VERSION ""

NS_ :

BS_:

BU_: BMC CMC_01 CMC_02 CMC_03 CMC_04 CMC_05 CMC_06 CMC_07 CMC_08
VAL_TABLE_ J1939_8bit 255 "Not available" 254 "Error" ;

BO_ 186 BMC_Request_voltages: 8 BMC
 SG_ BMC_Magic_content : 0|64@1+ (1,0) [4.97229944405885E+018|4.97229944405885E+018] "Unknown"  CMC_01,CMC_02,CMC_03,CMC_04,CMC_05,CMC_06,CMC_07,CMC_08

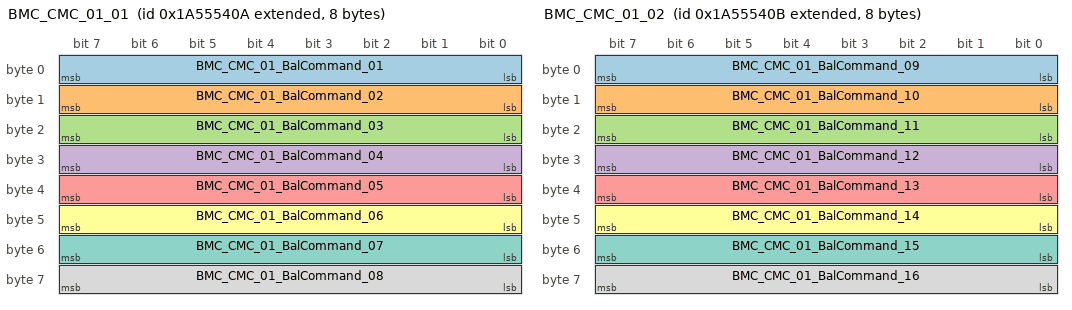
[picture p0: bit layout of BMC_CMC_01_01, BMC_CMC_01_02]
BO_ 2589283338 BMC_CMC_01_01: 8 BMC
 SG_ BMC_CMC_01_BalCommand_01 : 0|8@1+ (2,0) [0|506] "Minute"  CMC_01
 SG_ BMC_CMC_01_BalCommand_02 : 8|8@1+ (2,0) [0|506] "Minute"  CMC_01
 SG_ BMC_CMC_01_BalCommand_03 : 16|8@1+ (2,0) [0|506] "Minute"  CMC_01
 SG_ BMC_CMC_01_BalCommand_04 : 24|8@1+ (2,0) [0|506] "Minute"  CMC_01
 SG_ BMC_CMC_01_BalCommand_05 : 32|8@1+ (2,0) [0|506] "Minute"  CMC_01
 SG_ BMC_CMC_01_BalCommand_06 : 40|8@1+ (2,0) [0|506] "Minute"  CMC_01
 SG_ BMC_CMC_01_BalCommand_07 : 48|8@1+ (2,0) [0|506] "Minute"  CMC_01
 SG_ BMC_CMC_01_BalCommand_08 : 56|8@1+ (2,0) [0|506] "Minute"  CMC_01

BO_ 2589283339 BMC_CMC_01_02: 8 BMC
 SG_ BMC_CMC_01_BalCommand_09 : 0|8@1+ (2,0) [0|506] "Minute"  CMC_01
 SG_ BMC_CMC_01_BalCommand_10 : 8|8@1+ (2,0) [0|506] "Minute"  CMC_01
 SG_ BMC_CMC_01_BalCommand_11 : 16|8@1+ (2,0) [0|506] "Minute"  CMC_01
 SG_ BMC_CMC_01_BalCommand_12 : 24|8@1+ (2,0) [0|506] "Minute"  CMC_01
 SG_ BMC_CMC_01_BalCommand_13 : 32|8@1+ (2,0) [0|506] "Minute" Vector__XXX
 SG_ BMC_CMC_01_BalCommand_14 : 40|8@1+ (2,0) [0|506] "Minute" Vector__XXX
 SG_ BMC_CMC_01_BalCommand_15 : 48|8@1+ (2,0) [0|506] "Minute" Vector__XXX
 SG_ BMC_CMC_01_BalCommand_16 : 56|8@1+ (2,0) [0|506] "Minute" Vector__XXX

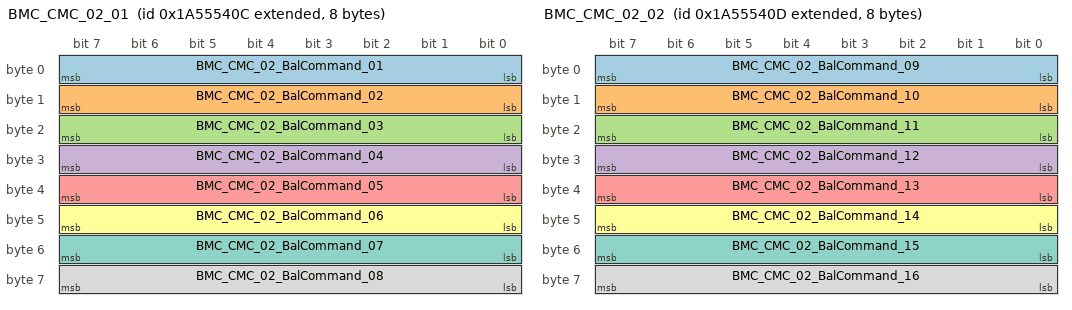
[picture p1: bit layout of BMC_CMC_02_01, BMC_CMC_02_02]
BO_ 2589283340 BMC_CMC_02_01: 8 BMC
 SG_ BMC_CMC_02_BalCommand_01 : 0|8@1+ (2,0) [0|506] "Minute"  CMC_02
 SG_ BMC_CMC_02_BalCommand_02 : 8|8@1+ (2,0) [0|506] "Minute"  CMC_02
 SG_ BMC_CMC_02_BalCommand_03 : 16|8@1+ (2,0) [0|506] "Minute"  CMC_02
 SG_ BMC_CMC_02_BalCommand_04 : 24|8@1+ (2,0) [0|506] "Minute"  CMC_02
 SG_ BMC_CMC_02_BalCommand_05 : 32|8@1+ (2,0) [0|506] "Minute"  CMC_02
 SG_ BMC_CMC_02_BalCommand_06 : 40|8@1+ (2,0) [0|506] "Minute"  CMC_02
 SG_ BMC_CMC_02_BalCommand_07 : 48|8@1+ (2,0) [0|506] "Minute"  CMC_02
 SG_ BMC_CMC_02_BalCommand_08 : 56|8@1+ (2,0) [0|506] "Minute"  CMC_02

BO_ 2589283341 BMC_CMC_02_02: 8 BMC
 SG_ BMC_CMC_02_BalCommand_09 : 0|8@1+ (2,0) [0|506] "Minute"  CMC_02
 SG_ BMC_CMC_02_BalCommand_10 : 8|8@1+ (2,0) [0|506] "Minute"  CMC_02
 SG_ BMC_CMC_02_BalCommand_11 : 16|8@1+ (2,0) [0|506] "Minute"  CMC_02
 SG_ BMC_CMC_02_BalCommand_12 : 24|8@1+ (2,0) [0|506] "Minute"  CMC_02
 SG_ BMC_CMC_02_BalCommand_13 : 32|8@1+ (2,0) [0|506] "Minute" Vector__XXX
 SG_ BMC_CMC_02_BalCommand_14 : 40|8@1+ (2,0) [0|506] "Minute" Vector__XXX
 SG_ BMC_CMC_02_BalCommand_15 : 48|8@1+ (2,0) [0|506] "Minute" Vector__XXX
 SG_ BMC_CMC_02_BalCommand_16 : 56|8@1+ (2,0) [0|506] "Minute" Vector__XXX

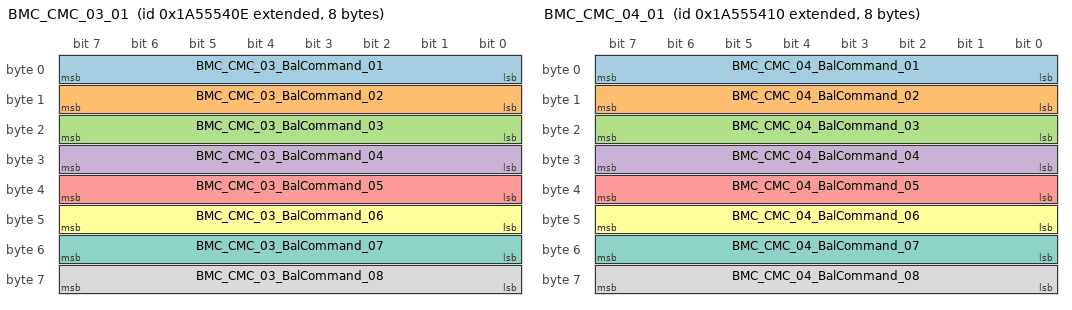
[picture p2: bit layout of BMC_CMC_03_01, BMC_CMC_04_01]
BO_ 2589283342 BMC_CMC_03_01: 8 BMC
 SG_ BMC_CMC_03_BalCommand_01 : 0|8@1+ (2,0) [0|506] "Minute"  CMC_03
 SG_ BMC_CMC_03_BalCommand_02 : 8|8@1+ (2,0) [0|506] "Minute"  CMC_03
 SG_ BMC_CMC_03_BalCommand_03 : 16|8@1+ (2,0) [0|506] "Minute"  CMC_03
 SG_ BMC_CMC_03_BalCommand_04 : 24|8@1+ (2,0) [0|506] "Minute"  CMC_03
 SG_ BMC_CMC_03_BalCommand_05 : 32|8@1+ (2,0) [0|506] "Minute"  CMC_03
 SG_ BMC_CMC_03_BalCommand_06 : 40|8@1+ (2,0) [0|506] "Minute"  CMC_03
 SG_ BMC_CMC_03_BalCommand_07 : 48|8@1+ (2,0) [0|506] "Minute"  CMC_03
 SG_ BMC_CMC_03_BalCommand_08 : 56|8@1+ (2,0) [0|506] "Minute"  CMC_03

BO_ 2589283344 BMC_CMC_04_01: 8 BMC
 SG_ BMC_CMC_04_BalCommand_01 : 0|8@1+ (2,0) [0|506] "Minute"  CMC_04
 SG_ BMC_CMC_04_BalCommand_02 : 8|8@1+ (2,0) [0|506] "Minute"  CMC_04
 SG_ BMC_CMC_04_BalCommand_03 : 16|8@1+ (2,0) [0|506] "Minute"  CMC_04
 SG_ BMC_CMC_04_BalCommand_04 : 24|8@1+ (2,0) [0|506] "Minute"  CMC_04
 SG_ BMC_CMC_04_BalCommand_05 : 32|8@1+ (2,0) [0|506] "Minute"  CMC_04
 SG_ BMC_CMC_04_BalCommand_06 : 40|8@1+ (2,0) [0|506] "Minute"  CMC_04
 SG_ BMC_CMC_04_BalCommand_07 : 48|8@1+ (2,0) [0|506] "Minute"  CMC_04
 SG_ BMC_CMC_04_BalCommand_08 : 56|8@1+ (2,0) [0|506] "Minute"  CMC_04

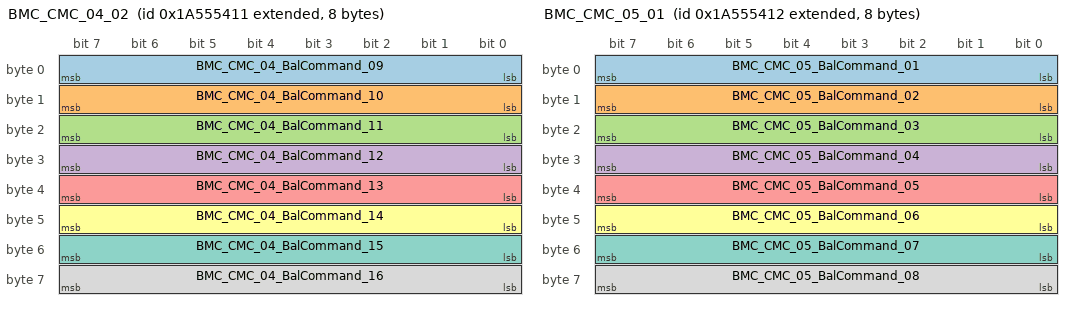
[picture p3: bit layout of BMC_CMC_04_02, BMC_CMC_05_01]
BO_ 2589283345 BMC_CMC_04_02: 8 BMC
 SG_ BMC_CMC_04_BalCommand_09 : 0|8@1+ (2,0) [0|506] "Minute"  CMC_04
 SG_ BMC_CMC_04_BalCommand_10 : 8|8@1+ (2,0) [0|506] "Minute"  CMC_04
 SG_ BMC_CMC_04_BalCommand_11 : 16|8@1+ (2,0) [0|506] "Minute" Vector__XXX
 SG_ BMC_CMC_04_BalCommand_12 : 24|8@1+ (2,0) [0|506] "Minute" Vector__XXX
 SG_ BMC_CMC_04_BalCommand_13 : 32|8@1+ (2,0) [0|506] "Minute" Vector__XXX
 SG_ BMC_CMC_04_BalCommand_14 : 40|8@1+ (2,0) [0|506] "Minute" Vector__XXX
 SG_ BMC_CMC_04_BalCommand_15 : 48|8@1+ (2,0) [0|506] "Minute" Vector__XXX
 SG_ BMC_CMC_04_BalCommand_16 : 56|8@1+ (2,0) [0|506] "Minute" Vector__XXX

BO_ 2589283346 BMC_CMC_05_01: 8 BMC
 SG_ BMC_CMC_05_BalCommand_01 : 0|8@1+ (2,0) [0|506] "Minute"  CMC_05
 SG_ BMC_CMC_05_BalCommand_02 : 8|8@1+ (2,0) [0|506] "Minute"  CMC_05
 SG_ BMC_CMC_05_BalCommand_03 : 16|8@1+ (2,0) [0|506] "Minute"  CMC_05
 SG_ BMC_CMC_05_BalCommand_04 : 24|8@1+ (2,0) [0|506] "Minute"  CMC_05
 SG_ BMC_CMC_05_BalCommand_05 : 32|8@1+ (2,0) [0|506] "Minute"  CMC_05
 SG_ BMC_CMC_05_BalCommand_06 : 40|8@1+ (2,0) [0|506] "Minute"  CMC_05
 SG_ BMC_CMC_05_BalCommand_07 : 48|8@1+ (2,0) [0|506] "Minute"  CMC_05
 SG_ BMC_CMC_05_BalCommand_08 : 56|8@1+ (2,0) [0|506] "Minute"  CMC_05

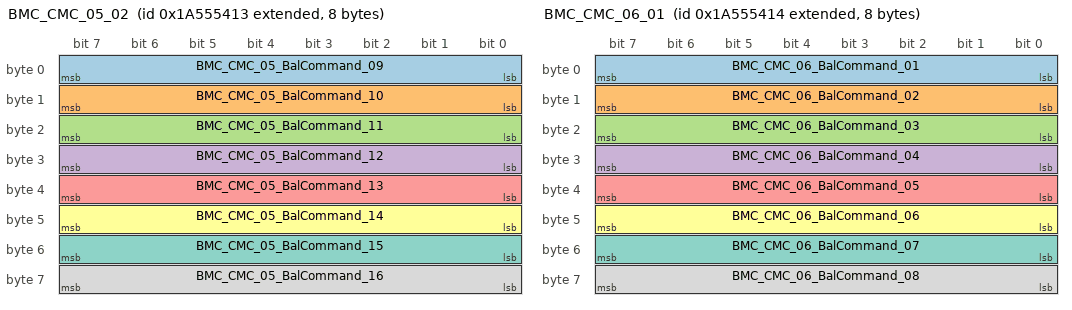
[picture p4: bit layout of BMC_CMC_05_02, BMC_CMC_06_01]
BO_ 2589283347 BMC_CMC_05_02: 8 BMC
 SG_ BMC_CMC_05_BalCommand_09 : 0|8@1+ (2,0) [0|506] "Minute"  CMC_05
 SG_ BMC_CMC_05_BalCommand_10 : 8|8@1+ (2,0) [0|506] "Minute"  CMC_05
 SG_ BMC_CMC_05_BalCommand_11 : 16|8@1+ (2,0) [0|506] "Minute"  CMC_05
 SG_ BMC_CMC_05_BalCommand_12 : 24|8@1+ (2,0) [0|506] "Minute"  CMC_05
 SG_ BMC_CMC_05_BalCommand_13 : 32|8@1+ (2,0) [0|506] "Minute" Vector__XXX
 SG_ BMC_CMC_05_BalCommand_14 : 40|8@1+ (2,0) [0|506] "Minute" Vector__XXX
 SG_ BMC_CMC_05_BalCommand_15 : 48|8@1+ (2,0) [0|506] "Minute" Vector__XXX
 SG_ BMC_CMC_05_BalCommand_16 : 56|8@1+ (2,0) [0|506] "Minute" Vector__XXX

BO_ 2589283348 BMC_CMC_06_01: 8 BMC
 SG_ BMC_CMC_06_BalCommand_01 : 0|8@1+ (2,0) [0|506] "Minute"  CMC_06
 SG_ BMC_CMC_06_BalCommand_02 : 8|8@1+ (2,0) [0|506] "Minute"  CMC_06
 SG_ BMC_CMC_06_BalCommand_03 : 16|8@1+ (2,0) [0|506] "Minute"  CMC_06
 SG_ BMC_CMC_06_BalCommand_04 : 24|8@1+ (2,0) [0|506] "Minute"  CMC_06
 SG_ BMC_CMC_06_BalCommand_05 : 32|8@1+ (2,0) [0|506] "Minute"  CMC_06
 SG_ BMC_CMC_06_BalCommand_06 : 40|8@1+ (2,0) [0|506] "Minute"  CMC_06
 SG_ BMC_CMC_06_BalCommand_07 : 48|8@1+ (2,0) [0|506] "Minute"  CMC_06
 SG_ BMC_CMC_06_BalCommand_08 : 56|8@1+ (2,0) [0|506] "Minute"  CMC_06

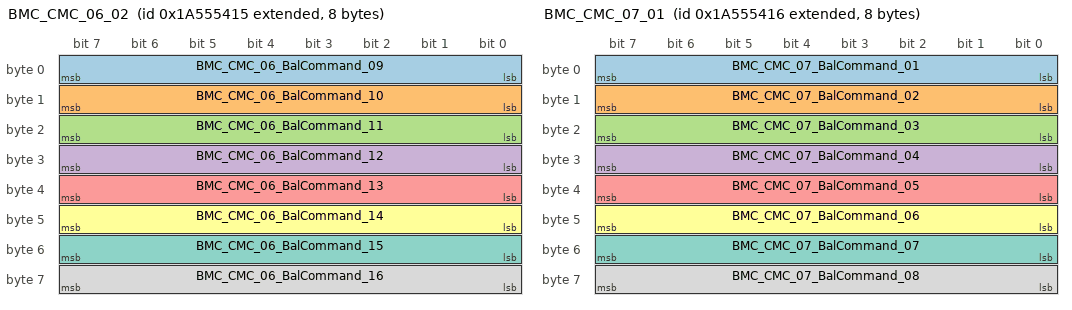
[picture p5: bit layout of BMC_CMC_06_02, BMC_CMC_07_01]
BO_ 2589283349 BMC_CMC_06_02: 8 BMC
 SG_ BMC_CMC_06_BalCommand_09 : 0|8@1+ (2,0) [0|506] "Minute"  CMC_06
 SG_ BMC_CMC_06_BalCommand_10 : 8|8@1+ (2,0) [0|506] "Minute"  CMC_06
 SG_ BMC_CMC_06_BalCommand_11 : 16|8@1+ (2,0) [0|506] "Minute"  CMC_06
 SG_ BMC_CMC_06_BalCommand_12 : 24|8@1+ (2,0) [0|506] "Minute"  CMC_06
 SG_ BMC_CMC_06_BalCommand_13 : 32|8@1+ (2,0) [0|506] "Minute" Vector__XXX
 SG_ BMC_CMC_06_BalCommand_14 : 40|8@1+ (2,0) [0|506] "Minute" Vector__XXX
 SG_ BMC_CMC_06_BalCommand_15 : 48|8@1+ (2,0) [0|506] "Minute" Vector__XXX
 SG_ BMC_CMC_06_BalCommand_16 : 56|8@1+ (2,0) [0|506] "Minute" Vector__XXX

BO_ 2589283350 BMC_CMC_07_01: 8 BMC
 SG_ BMC_CMC_07_BalCommand_01 : 0|8@1+ (2,0) [0|506] "Minute"  CMC_07
 SG_ BMC_CMC_07_BalCommand_02 : 8|8@1+ (2,0) [0|506] "Minute"  CMC_07
 SG_ BMC_CMC_07_BalCommand_03 : 16|8@1+ (2,0) [0|506] "Minute"  CMC_07
 SG_ BMC_CMC_07_BalCommand_04 : 24|8@1+ (2,0) [0|506] "Minute"  CMC_07
 SG_ BMC_CMC_07_BalCommand_05 : 32|8@1+ (2,0) [0|506] "Minute"  CMC_07
 SG_ BMC_CMC_07_BalCommand_06 : 40|8@1+ (2,0) [0|506] "Minute"  CMC_07
 SG_ BMC_CMC_07_BalCommand_07 : 48|8@1+ (2,0) [0|506] "Minute"  CMC_07
 SG_ BMC_CMC_07_BalCommand_08 : 56|8@1+ (2,0) [0|506] "Minute"  CMC_07

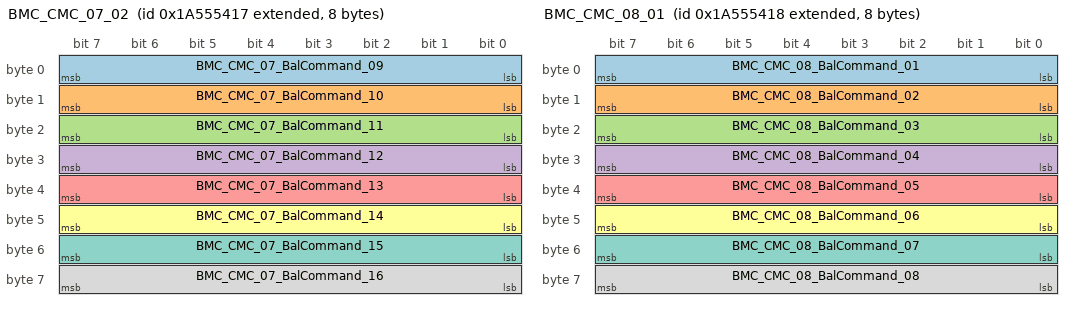
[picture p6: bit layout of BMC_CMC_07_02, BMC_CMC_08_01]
BO_ 2589283351 BMC_CMC_07_02: 8 BMC
 SG_ BMC_CMC_07_BalCommand_09 : 0|8@1+ (2,0) [0|506] "Minute"  CMC_07
 SG_ BMC_CMC_07_BalCommand_10 : 8|8@1+ (2,0) [0|506] "Minute"  CMC_07
 SG_ BMC_CMC_07_BalCommand_11 : 16|8@1+ (2,0) [0|506] "Minute"  CMC_07
 SG_ BMC_CMC_07_BalCommand_12 : 24|8@1+ (2,0) [0|506] "Minute"  CMC_07
 SG_ BMC_CMC_07_BalCommand_13 : 32|8@1+ (2,0) [0|506] "Minute" Vector__XXX
 SG_ BMC_CMC_07_BalCommand_14 : 40|8@1+ (2,0) [0|506] "Minute" Vector__XXX
 SG_ BMC_CMC_07_BalCommand_15 : 48|8@1+ (2,0) [0|506] "Minute" Vector__XXX
 SG_ BMC_CMC_07_BalCommand_16 : 56|8@1+ (2,0) [0|506] "Minute" Vector__XXX

BO_ 2589283352 BMC_CMC_08_01: 8 BMC
 SG_ BMC_CMC_08_BalCommand_01 : 0|8@1+ (2,0) [0|506] "Minute"  CMC_08
 SG_ BMC_CMC_08_BalCommand_02 : 8|8@1+ (2,0) [0|506] "Minute"  CMC_08
 SG_ BMC_CMC_08_BalCommand_03 : 16|8@1+ (2,0) [0|506] "Minute"  CMC_08
 SG_ BMC_CMC_08_BalCommand_04 : 24|8@1+ (2,0) [0|506] "Minute"  CMC_08
 SG_ BMC_CMC_08_BalCommand_05 : 32|8@1+ (2,0) [0|506] "Minute"  CMC_08
 SG_ BMC_CMC_08_BalCommand_06 : 40|8@1+ (2,0) [0|506] "Minute"  CMC_08
 SG_ BMC_CMC_08_BalCommand_07 : 48|8@1+ (2,0) [0|506] "Minute"  CMC_08
 SG_ BMC_CMC_08_BalCommand_08 : 56|8@1+ (2,0) [0|506] "Minute"  CMC_08

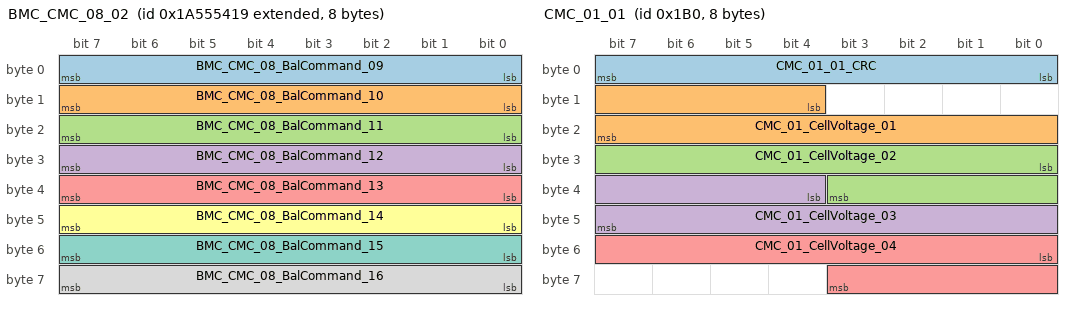
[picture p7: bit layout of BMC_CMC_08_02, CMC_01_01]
BO_ 2589283353 BMC_CMC_08_02: 8 BMC
 SG_ BMC_CMC_08_BalCommand_09 : 0|8@1+ (2,0) [0|506] "Minute"  CMC_08
 SG_ BMC_CMC_08_BalCommand_10 : 8|8@1+ (2,0) [0|506] "Minute"  CMC_08
 SG_ BMC_CMC_08_BalCommand_11 : 16|8@1+ (2,0) [0|506] "Minute" Vector__XXX
 SG_ BMC_CMC_08_BalCommand_12 : 24|8@1+ (2,0) [0|506] "Minute" Vector__XXX
 SG_ BMC_CMC_08_BalCommand_13 : 32|8@1+ (2,0) [0|506] "Minute" Vector__XXX
 SG_ BMC_CMC_08_BalCommand_14 : 40|8@1+ (2,0) [0|506] "Minute" Vector__XXX
 SG_ BMC_CMC_08_BalCommand_15 : 48|8@1+ (2,0) [0|506] "Minute" Vector__XXX
 SG_ BMC_CMC_08_BalCommand_16 : 56|8@1+ (2,0) [0|506] "Minute" Vector__XXX

BO_ 432 CMC_01_01: 8 CMC_01
 SG_ CMC_01_01_CRC : 0|8@1+ (1,0) [0|255] ""  BMC
 SG_ CMC_01_CellVoltage_01 : 12|12@1+ (1,1000) [1000|5091] "MilliVolt"  BMC
 SG_ CMC_01_CellVoltage_02 : 24|12@1+ (1,1000) [1000|5091] "MilliVolt"  BMC
 SG_ CMC_01_CellVoltage_03 : 36|12@1+ (1,1000) [1000|5091] "MilliVolt"  BMC
 SG_ CMC_01_CellVoltage_04 : 48|12@1+ (1,1000) [1000|5091] "MilliVolt"  BMC

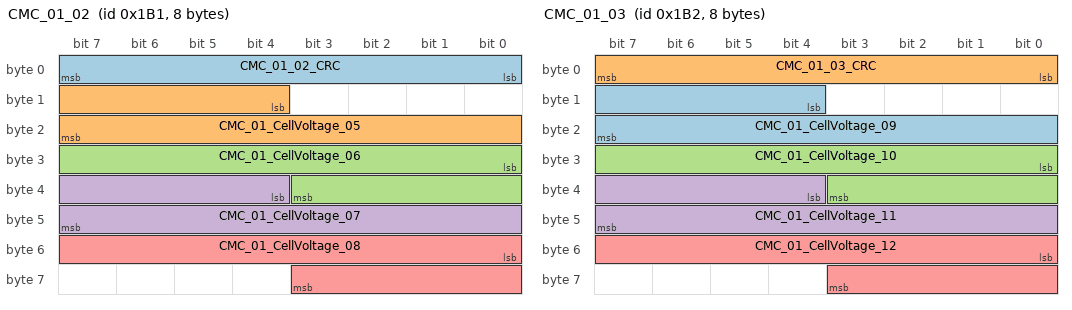
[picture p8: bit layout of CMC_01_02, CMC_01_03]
BO_ 433 CMC_01_02: 8 CMC_01
 SG_ CMC_01_02_CRC : 0|8@1+ (1,0) [0|255] ""  BMC
 SG_ CMC_01_CellVoltage_05 : 12|12@1+ (1,1000) [1000|5091] "MilliVolt"  BMC
 SG_ CMC_01_CellVoltage_06 : 24|12@1+ (1,1000) [1000|5091] "MilliVolt"  BMC
 SG_ CMC_01_CellVoltage_07 : 36|12@1+ (1,1000) [1000|5091] "MilliVolt"  BMC
 SG_ CMC_01_CellVoltage_08 : 48|12@1+ (1,1000) [1000|5091] "MilliVolt"  BMC

BO_ 434 CMC_01_03: 8 CMC_01
 SG_ CMC_01_CellVoltage_09 : 12|12@1+ (1,1000) [1000|5091] "MilliVolt"  BMC
 SG_ CMC_01_03_CRC : 0|8@1+ (1,0) [0|255] ""  BMC
 SG_ CMC_01_CellVoltage_10 : 24|12@1+ (1,1000) [1000|5091] "MilliVolt"  BMC
 SG_ CMC_01_CellVoltage_11 : 36|12@1+ (1,1000) [1000|5091] "MilliVolt"  BMC
 SG_ CMC_01_CellVoltage_12 : 48|12@1+ (1,1000) [1000|5091] "MilliVolt"  BMC

BO_ 2589283329 CMC_01_05: 8 CMC_01
 SG_ Cell_12_Balance_status : 27|1@1+ (1,0) [0|1] "" Vector__XXX
 SG_ Cell_11_Balance_status : 26|1@1+ (1,0) [0|1] "" Vector__XXX
 SG_ Cell_10_Balance_status : 25|1@1+ (1,0) [0|1] "" Vector__XXX
 SG_ Cell_09_Balance_status : 24|1@1+ (1,0) [0|1] "" Vector__XXX
 SG_ Cell_08_Balance_status : 23|1@1+ (1,0) [0|1] "" Vector__XXX
 SG_ Cell_07_Balance_status : 22|1@1+ (1,0) [0|1] "" Vector__XXX
 SG_ Cell_06_Balance_status : 21|1@1+ (1,0) [0|1] "" Vector__XXX
 SG_ Cell_05_Balance_status : 20|1@1+ (1,0) [0|1] "" Vector__XXX
 SG_ Cell_04_Balance_status : 19|1@1+ (1,0) [0|1] "" Vector__XXX
 SG_ Cell_03_Balance_status : 18|1@1+ (1,0) [0|1] "" Vector__XXX
 SG_ Cell_02_Balance_status : 17|1@1+ (1,0) [0|1] "" Vector__XXX
 SG_ Cell_01_Balance_status : 16|1@1+ (1,0) [0|1] "" Vector__XXX
 SG_ CMC_01_Temperature_0 : 0|8@1+ (0.5,-40) [-40|86] "DegreeCelcius" Vector__XXX
 SG_ CMC_01_Temperature_4 : 56|8@1+ (0.5,-40) [-40|86] "DegreeCelcius" Vector__XXX
 SG_ CMC_01_Temperature_3 : 48|8@1+ (0.5,-40) [-40|86] "DegreeCelcius" Vector__XXX
 SG_ CMC_01_Temperature_1 : 32|8@1+ (0.5,-40) [-40|86] "DegreeCelcius"  BMC
 SG_ CMC_01_Temperature_2 : 40|8@1+ (0.5,-40) [-40|86] "DegreeCelcius"  BMC

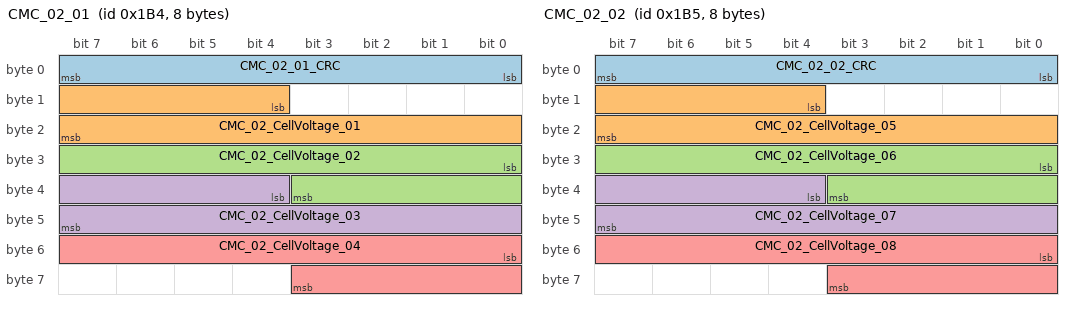
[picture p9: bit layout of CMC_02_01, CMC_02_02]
BO_ 436 CMC_02_01: 8 CMC_02
 SG_ CMC_02_01_CRC : 0|8@1+ (1,0) [0|255] ""  BMC
 SG_ CMC_02_CellVoltage_01 : 12|12@1+ (1,1000) [1000|5091] "MilliVolt"  BMC
 SG_ CMC_02_CellVoltage_02 : 24|12@1+ (1,1000) [1000|5091] "MilliVolt"  BMC
 SG_ CMC_02_CellVoltage_03 : 36|12@1+ (1,1000) [1000|5091] "MilliVolt"  BMC
 SG_ CMC_02_CellVoltage_04 : 48|12@1+ (1,1000) [1000|5091] "MilliVolt"  BMC

BO_ 437 CMC_02_02: 8 CMC_02
 SG_ CMC_02_02_CRC : 0|8@1+ (1,0) [0|255] ""  BMC
 SG_ CMC_02_CellVoltage_05 : 12|12@1+ (1,1000) [1000|5091] "MilliVolt"  BMC
 SG_ CMC_02_CellVoltage_06 : 24|12@1+ (1,1000) [1000|5091] "MilliVolt"  BMC
 SG_ CMC_02_CellVoltage_07 : 36|12@1+ (1,1000) [1000|5091] "MilliVolt"  BMC
 SG_ CMC_02_CellVoltage_08 : 48|12@1+ (1,1000) [1000|5091] "MilliVolt"  BMC

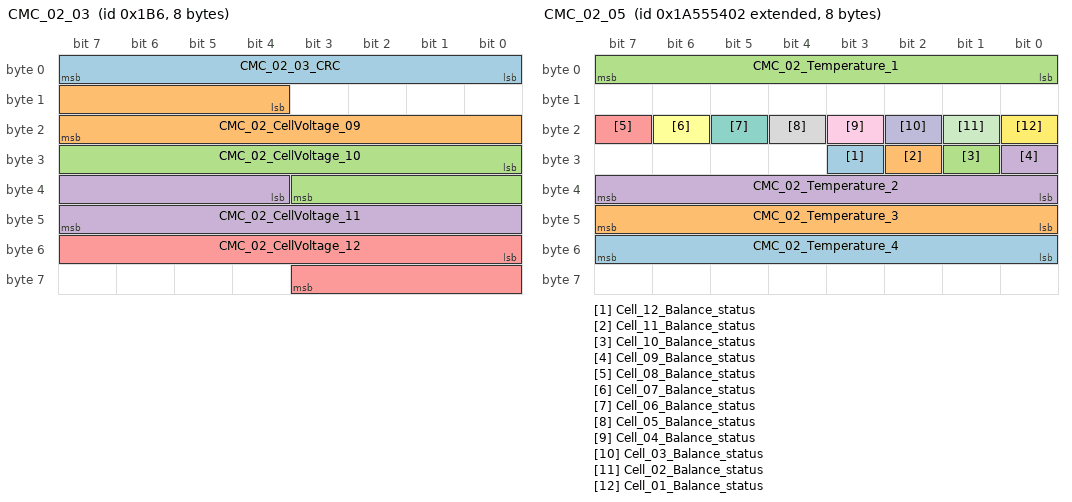
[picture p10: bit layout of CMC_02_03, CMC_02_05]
BO_ 438 CMC_02_03: 8 CMC_02
 SG_ CMC_02_03_CRC : 0|8@1+ (1,0) [0|255] ""  BMC
 SG_ CMC_02_CellVoltage_09 : 12|12@1+ (1,1000) [1000|5091] "MilliVolt"  BMC
 SG_ CMC_02_CellVoltage_10 : 24|12@1+ (1,1000) [1000|5091] "MilliVolt"  BMC
 SG_ CMC_02_CellVoltage_11 : 36|12@1+ (1,1000) [1000|5091] "MilliVolt"  BMC
 SG_ CMC_02_CellVoltage_12 : 48|12@1+ (1,1000) [1000|5091] "MilliVolt"  BMC

BO_ 2589283330 CMC_02_05: 8 CMC_02
 SG_ Cell_12_Balance_status : 27|1@1+ (1,0) [0|1] "" Vector__XXX
 SG_ Cell_11_Balance_status : 26|1@1+ (1,0) [0|1] "" Vector__XXX
 SG_ Cell_10_Balance_status : 25|1@1+ (1,0) [0|1] "" Vector__XXX
 SG_ Cell_09_Balance_status : 24|1@1+ (1,0) [0|1] "" Vector__XXX
 SG_ Cell_08_Balance_status : 23|1@1+ (1,0) [0|1] "" Vector__XXX
 SG_ Cell_07_Balance_status : 22|1@1+ (1,0) [0|1] "" Vector__XXX
 SG_ Cell_06_Balance_status : 21|1@1+ (1,0) [0|1] "" Vector__XXX
 SG_ Cell_05_Balance_status : 20|1@1+ (1,0) [0|1] "" Vector__XXX
 SG_ Cell_04_Balance_status : 19|1@1+ (1,0) [0|1] "" Vector__XXX
 SG_ Cell_03_Balance_status : 18|1@1+ (1,0) [0|1] "" Vector__XXX
 SG_ Cell_02_Balance_status : 17|1@1+ (1,0) [0|1] "" Vector__XXX
 SG_ Cell_01_Balance_status : 16|1@1+ (1,0) [0|1] "" Vector__XXX
 SG_ CMC_02_Temperature_4 : 48|8@1+ (0.5,-40) [-40|86] "DegreeCelcius" Vector__XXX
 SG_ CMC_02_Temperature_3 : 40|8@1+ (0.5,-40) [-40|86] "DegreeCelcius" Vector__XXX
 SG_ CMC_02_Temperature_1 : 0|8@1+ (0.5,-40) [-40|86] "DegreeCelcius"  BMC
 SG_ CMC_02_Temperature_2 : 32|8@1+ (0.5,-40) [-40|86] "DegreeCelcius"  BMC

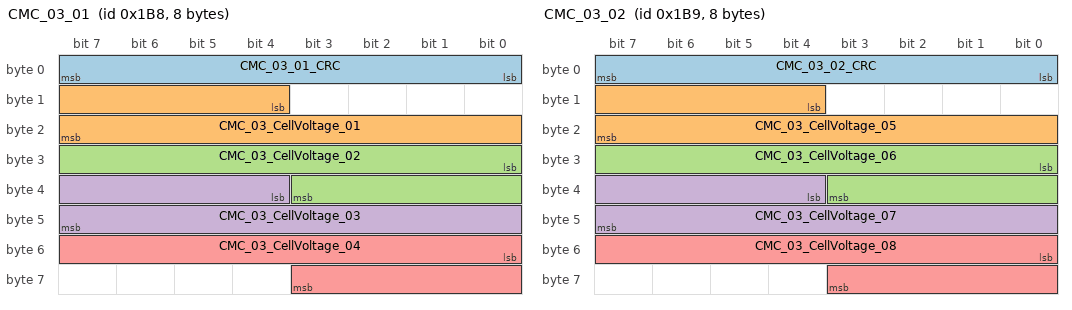
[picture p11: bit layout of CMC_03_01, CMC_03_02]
BO_ 440 CMC_03_01: 8 CMC_03
 SG_ CMC_03_01_CRC : 0|8@1+ (1,0) [0|255] ""  BMC
 SG_ CMC_03_CellVoltage_01 : 12|12@1+ (1,1000) [1000|5091] "MilliVolt"  BMC
 SG_ CMC_03_CellVoltage_02 : 24|12@1+ (1,1000) [1000|5091] "MilliVolt"  BMC
 SG_ CMC_03_CellVoltage_03 : 36|12@1+ (1,1000) [1000|5091] "MilliVolt"  BMC
 SG_ CMC_03_CellVoltage_04 : 48|12@1+ (1,1000) [1000|5091] "MilliVolt"  BMC

BO_ 441 CMC_03_02: 8 CMC_03
 SG_ CMC_03_02_CRC : 0|8@1+ (1,0) [0|255] ""  BMC
 SG_ CMC_03_CellVoltage_05 : 12|12@1+ (1,1000) [1000|5091] "MilliVolt"  BMC
 SG_ CMC_03_CellVoltage_06 : 24|12@1+ (1,1000) [1000|5091] "MilliVolt"  BMC
 SG_ CMC_03_CellVoltage_07 : 36|12@1+ (1,1000) [1000|5091] "MilliVolt"  BMC
 SG_ CMC_03_CellVoltage_08 : 48|12@1+ (1,1000) [1000|5091] "MilliVolt"  BMC

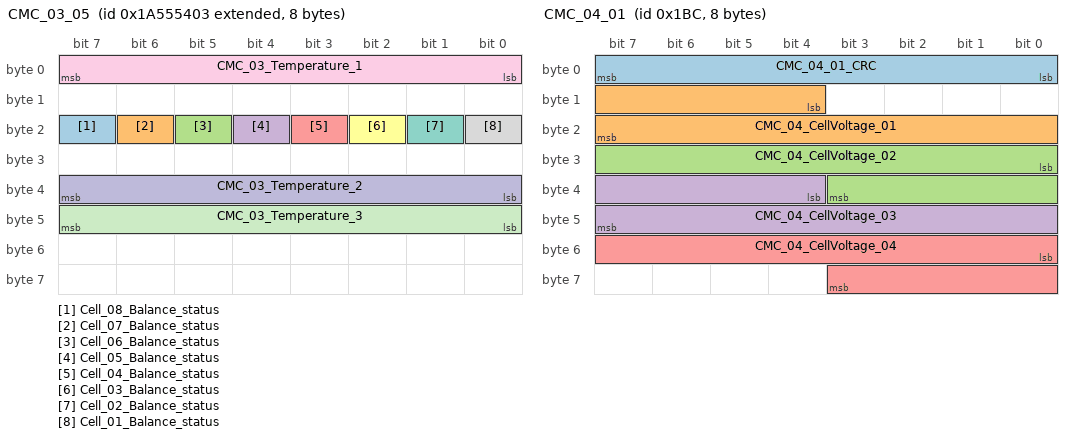
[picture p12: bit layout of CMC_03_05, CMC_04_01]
BO_ 2589283331 CMC_03_05: 8 CMC_03
 SG_ Cell_08_Balance_status : 23|1@1+ (1,0) [0|1] "" Vector__XXX
 SG_ Cell_07_Balance_status : 22|1@1+ (1,0) [0|1] "" Vector__XXX
 SG_ Cell_06_Balance_status : 21|1@1+ (1,0) [0|1] "" Vector__XXX
 SG_ Cell_05_Balance_status : 20|1@1+ (1,0) [0|1] "" Vector__XXX
 SG_ Cell_04_Balance_status : 19|1@1+ (1,0) [0|1] "" Vector__XXX
 SG_ Cell_03_Balance_status : 18|1@1+ (1,0) [0|1] "" Vector__XXX
 SG_ Cell_02_Balance_status : 17|1@1+ (1,0) [0|1] "" Vector__XXX
 SG_ Cell_01_Balance_status : 16|1@1+ (1,0) [0|1] "" Vector__XXX
 SG_ CMC_03_Temperature_1 : 0|8@1+ (0.5,-40) [-40|86] "DegreeCelcius"  BMC
 SG_ CMC_03_Temperature_2 : 32|8@1+ (0.5,-40) [-40|86] "DegreeCelcius"  BMC
 SG_ CMC_03_Temperature_3 : 40|8@1+ (0.5,-40) [-40|86] "DegreeCelcius"  BMC

BO_ 444 CMC_04_01: 8 CMC_04
 SG_ CMC_04_01_CRC : 0|8@1+ (1,0) [0|255] ""  BMC
 SG_ CMC_04_CellVoltage_01 : 12|12@1+ (1,1000) [1000|5091] "MilliVolt"  BMC
 SG_ CMC_04_CellVoltage_02 : 24|12@1+ (1,1000) [1000|5091] "MilliVolt"  BMC
 SG_ CMC_04_CellVoltage_03 : 36|12@1+ (1,1000) [1000|5091] "MilliVolt"  BMC
 SG_ CMC_04_CellVoltage_04 : 48|12@1+ (1,1000) [1000|5091] "MilliVolt"  BMC

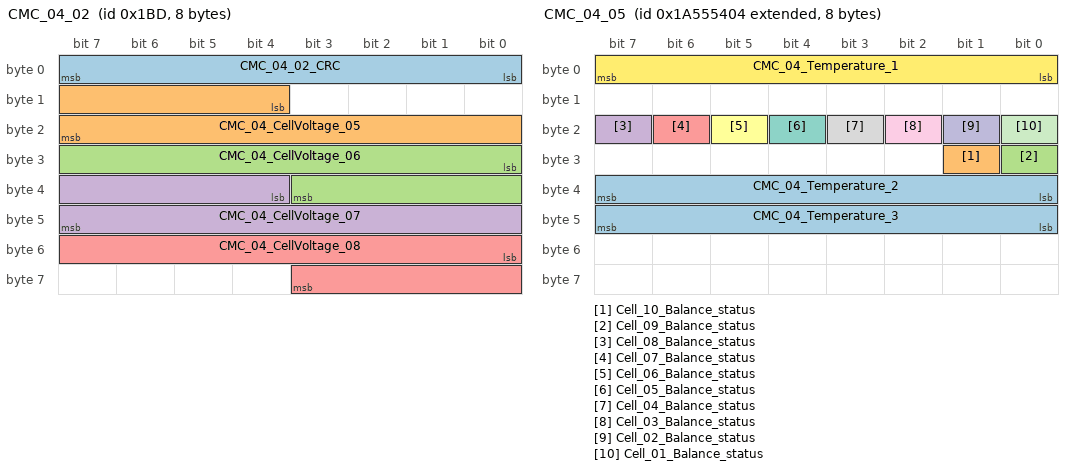
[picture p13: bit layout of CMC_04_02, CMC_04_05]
BO_ 445 CMC_04_02: 8 CMC_04
 SG_ CMC_04_02_CRC : 0|8@1+ (1,0) [0|255] ""  BMC
 SG_ CMC_04_CellVoltage_05 : 12|12@1+ (1,1000) [1000|5091] "MilliVolt"  BMC
 SG_ CMC_04_CellVoltage_06 : 24|12@1+ (1,1000) [1000|5091] "MilliVolt"  BMC
 SG_ CMC_04_CellVoltage_07 : 36|12@1+ (1,1000) [1000|5091] "MilliVolt"  BMC
 SG_ CMC_04_CellVoltage_08 : 48|12@1+ (1,1000) [1000|5091] "MilliVolt"  BMC

BO_ 446 CMC_04_03: 8 CMC_04
 SG_ CMC_04_03_CRC : 0|8@1+ (1,0) [0|255] ""  BMC
 SG_ CMC_04_CellVoltage_09 : 12|12@1+ (1,1000) [1000|5091] "MilliVolt"  BMC
 SG_ CMC_04_CellVoltage_10 : 24|12@1+ (1,1000) [1000|5091] "MilliVolt"  BMC

BO_ 2589283332 CMC_04_05: 8 CMC_04
 SG_ CMC_04_Temperature_3 : 40|8@1+ (0.5,-40) [-40|86] "DegreeCelcius" Vector__XXX
 SG_ Cell_10_Balance_status : 25|1@1+ (1,0) [0|1] "" Vector__XXX
 SG_ Cell_09_Balance_status : 24|1@1+ (1,0) [0|1] "" Vector__XXX
 SG_ Cell_08_Balance_status : 23|1@1+ (1,0) [0|1] "" Vector__XXX
 SG_ Cell_07_Balance_status : 22|1@1+ (1,0) [0|1] "" Vector__XXX
 SG_ Cell_06_Balance_status : 21|1@1+ (1,0) [0|1] "" Vector__XXX
 SG_ Cell_05_Balance_status : 20|1@1+ (1,0) [0|1] "" Vector__XXX
 SG_ Cell_04_Balance_status : 19|1@1+ (1,0) [0|1] "" Vector__XXX
 SG_ Cell_03_Balance_status : 18|1@1+ (1,0) [0|1] "" Vector__XXX
 SG_ Cell_02_Balance_status : 17|1@1+ (1,0) [0|1] "" Vector__XXX
 SG_ Cell_01_Balance_status : 16|1@1+ (1,0) [0|1] "" Vector__XXX
 SG_ CMC_04_Temperature_1 : 0|8@1+ (0.5,-40) [-40|86] "DegreeCelcius"  BMC
 SG_ CMC_04_Temperature_2 : 32|8@1+ (0.5,-40) [-40|86] "DegreeCelcius"  BMC

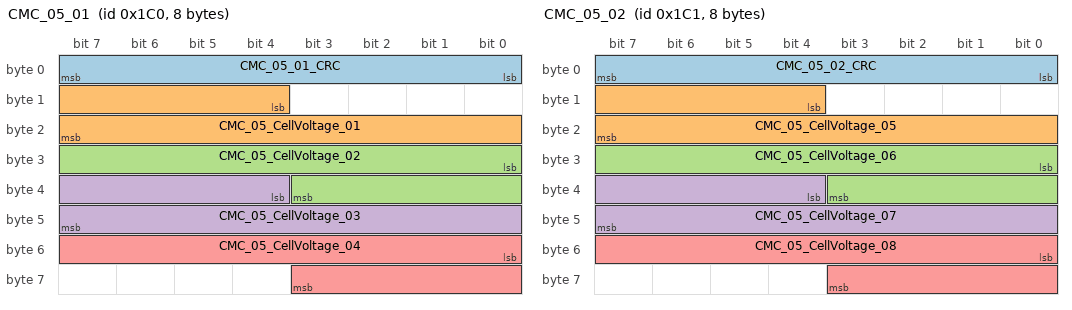
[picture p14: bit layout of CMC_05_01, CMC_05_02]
BO_ 448 CMC_05_01: 8 CMC_05
 SG_ CMC_05_01_CRC : 0|8@1+ (1,0) [0|255] ""  BMC
 SG_ CMC_05_CellVoltage_01 : 12|12@1+ (1,1000) [1000|5091] "MilliVolt"  BMC
 SG_ CMC_05_CellVoltage_02 : 24|12@1+ (1,1000) [1000|5091] "MilliVolt"  BMC
 SG_ CMC_05_CellVoltage_03 : 36|12@1+ (1,1000) [1000|5091] "MilliVolt"  BMC
 SG_ CMC_05_CellVoltage_04 : 48|12@1+ (1,1000) [1000|5091] "MilliVolt"  BMC

BO_ 449 CMC_05_02: 8 CMC_05
 SG_ CMC_05_02_CRC : 0|8@1+ (1,0) [0|255] ""  BMC
 SG_ CMC_05_CellVoltage_05 : 12|12@1+ (1,1000) [1000|5091] "MilliVolt"  BMC
 SG_ CMC_05_CellVoltage_06 : 24|12@1+ (1,1000) [1000|5091] "MilliVolt"  BMC
 SG_ CMC_05_CellVoltage_07 : 36|12@1+ (1,1000) [1000|5091] "MilliVolt"  BMC
 SG_ CMC_05_CellVoltage_08 : 48|12@1+ (1,1000) [1000|5091] "MilliVolt"  BMC

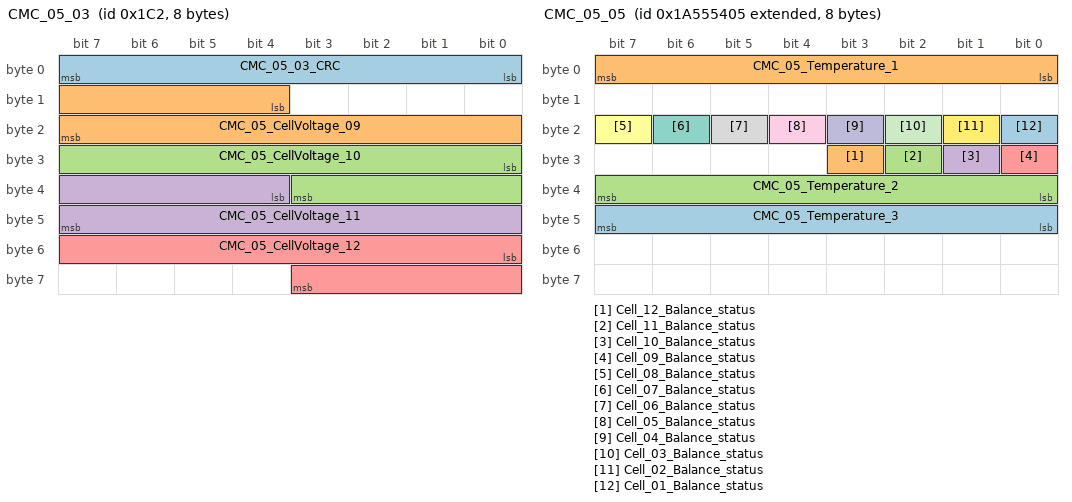
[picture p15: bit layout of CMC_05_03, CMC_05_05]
BO_ 450 CMC_05_03: 8 CMC_05
 SG_ CMC_05_03_CRC : 0|8@1+ (1,0) [0|255] ""  BMC
 SG_ CMC_05_CellVoltage_09 : 12|12@1+ (1,1000) [1000|5091] "MilliVolt"  BMC
 SG_ CMC_05_CellVoltage_10 : 24|12@1+ (1,1000) [1000|5091] "MilliVolt"  BMC
 SG_ CMC_05_CellVoltage_11 : 36|12@1+ (1,1000) [1000|5091] "MilliVolt"  BMC
 SG_ CMC_05_CellVoltage_12 : 48|12@1+ (1,1000) [1000|5091] "MilliVolt"  BMC

BO_ 2589283333 CMC_05_05: 8 CMC_05
 SG_ CMC_05_Temperature_3 : 40|8@1+ (0.5,-40) [-40|86] "DegreeCelcius" Vector__XXX
 SG_ Cell_12_Balance_status : 27|1@1+ (1,0) [0|1] "" Vector__XXX
 SG_ Cell_11_Balance_status : 26|1@1+ (1,0) [0|1] "" Vector__XXX
 SG_ Cell_10_Balance_status : 25|1@1+ (1,0) [0|1] "" Vector__XXX
 SG_ Cell_09_Balance_status : 24|1@1+ (1,0) [0|1] "" Vector__XXX
 SG_ Cell_08_Balance_status : 23|1@1+ (1,0) [0|1] "" Vector__XXX
 SG_ Cell_07_Balance_status : 22|1@1+ (1,0) [0|1] "" Vector__XXX
 SG_ Cell_06_Balance_status : 21|1@1+ (1,0) [0|1] "" Vector__XXX
 SG_ Cell_05_Balance_status : 20|1@1+ (1,0) [0|1] "" Vector__XXX
 SG_ Cell_04_Balance_status : 19|1@1+ (1,0) [0|1] "" Vector__XXX
 SG_ Cell_03_Balance_status : 18|1@1+ (1,0) [0|1] "" Vector__XXX
 SG_ Cell_02_Balance_status : 17|1@1+ (1,0) [0|1] "" Vector__XXX
 SG_ Cell_01_Balance_status : 16|1@1+ (1,0) [0|1] "" Vector__XXX
 SG_ CMC_05_Temperature_1 : 0|8@1+ (0.5,-40) [-40|86] "DegreeCelcius"  BMC
 SG_ CMC_05_Temperature_2 : 32|8@1+ (0.5,-40) [-40|86] "DegreeCelcius"  BMC

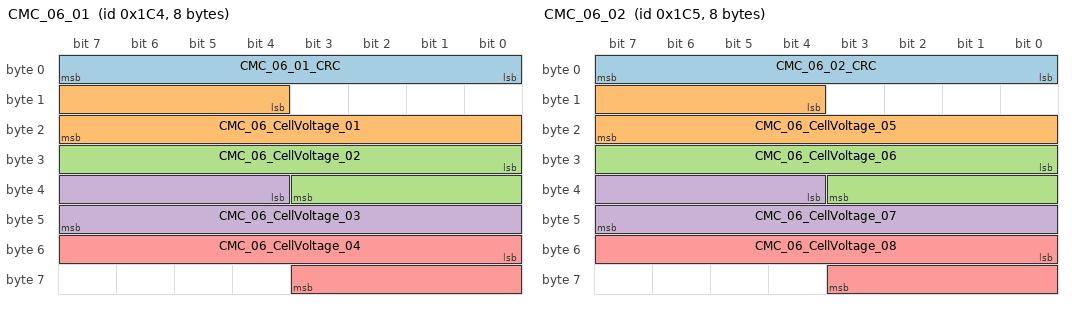
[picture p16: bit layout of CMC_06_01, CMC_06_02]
BO_ 452 CMC_06_01: 8 CMC_06
 SG_ CMC_06_01_CRC : 0|8@1+ (1,0) [0|255] ""  BMC
 SG_ CMC_06_CellVoltage_01 : 12|12@1+ (1,1000) [1000|5091] "MilliVolt"  BMC
 SG_ CMC_06_CellVoltage_02 : 24|12@1+ (1,1000) [1000|5091] "MilliVolt"  BMC
 SG_ CMC_06_CellVoltage_03 : 36|12@1+ (1,1000) [1000|5091] "MilliVolt"  BMC
 SG_ CMC_06_CellVoltage_04 : 48|12@1+ (1,1000) [1000|5091] "MilliVolt"  BMC

BO_ 453 CMC_06_02: 8 CMC_06
 SG_ CMC_06_02_CRC : 0|8@1+ (1,0) [0|255] ""  BMC
 SG_ CMC_06_CellVoltage_05 : 12|12@1+ (1,1000) [1000|5091] "MilliVolt"  BMC
 SG_ CMC_06_CellVoltage_06 : 24|12@1+ (1,1000) [1000|5091] "MilliVolt"  BMC
 SG_ CMC_06_CellVoltage_07 : 36|12@1+ (1,1000) [1000|5091] "MilliVolt"  BMC
 SG_ CMC_06_CellVoltage_08 : 48|12@1+ (1,1000) [1000|5091] "MilliVolt"  BMC

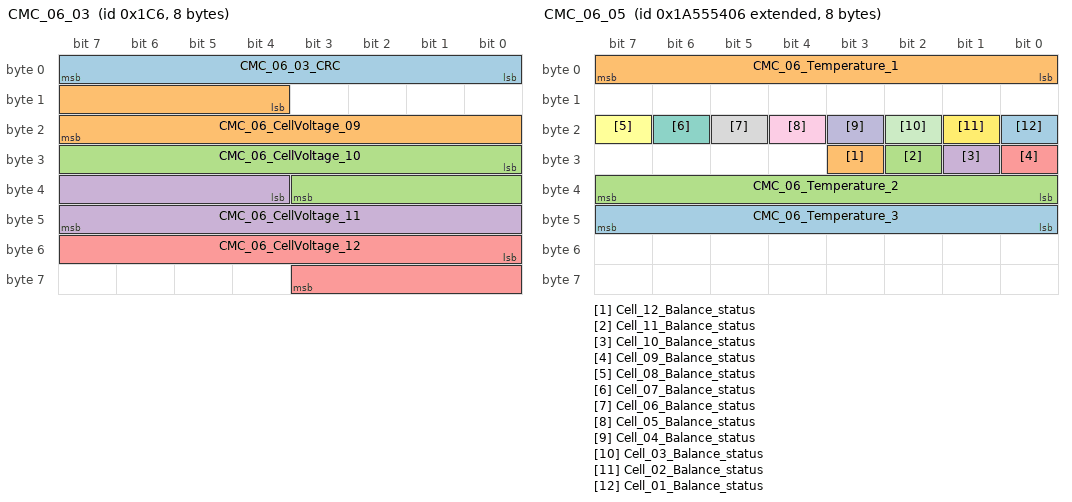
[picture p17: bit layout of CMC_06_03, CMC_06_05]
BO_ 454 CMC_06_03: 8 CMC_06
 SG_ CMC_06_03_CRC : 0|8@1+ (1,0) [0|255] ""  BMC
 SG_ CMC_06_CellVoltage_09 : 12|12@1+ (1,1000) [1000|5091] "MilliVolt"  BMC
 SG_ CMC_06_CellVoltage_10 : 24|12@1+ (1,1000) [1000|5091] "MilliVolt"  BMC
 SG_ CMC_06_CellVoltage_11 : 36|12@1+ (1,1000) [1000|5091] "MilliVolt"  BMC
 SG_ CMC_06_CellVoltage_12 : 48|12@1+ (1,1000) [1000|5091] "MilliVolt"  BMC

BO_ 2589283334 CMC_06_05: 8 CMC_06
 SG_ CMC_06_Temperature_3 : 40|8@1+ (0.5,-40) [-40|86] "DegreeCelcius" Vector__XXX
 SG_ Cell_12_Balance_status : 27|1@1+ (1,0) [0|1] "" Vector__XXX
 SG_ Cell_11_Balance_status : 26|1@1+ (1,0) [0|1] "" Vector__XXX
 SG_ Cell_10_Balance_status : 25|1@1+ (1,0) [0|1] "" Vector__XXX
 SG_ Cell_09_Balance_status : 24|1@1+ (1,0) [0|1] "" Vector__XXX
 SG_ Cell_08_Balance_status : 23|1@1+ (1,0) [0|1] "" Vector__XXX
 SG_ Cell_07_Balance_status : 22|1@1+ (1,0) [0|1] "" Vector__XXX
 SG_ Cell_06_Balance_status : 21|1@1+ (1,0) [0|1] "" Vector__XXX
 SG_ Cell_05_Balance_status : 20|1@1+ (1,0) [0|1] "" Vector__XXX
 SG_ Cell_04_Balance_status : 19|1@1+ (1,0) [0|1] "" Vector__XXX
 SG_ Cell_03_Balance_status : 18|1@1+ (1,0) [0|1] "" Vector__XXX
 SG_ Cell_02_Balance_status : 17|1@1+ (1,0) [0|1] "" Vector__XXX
 SG_ Cell_01_Balance_status : 16|1@1+ (1,0) [0|1] "" Vector__XXX
 SG_ CMC_06_Temperature_1 : 0|8@1+ (0.5,-40) [-40|86] "DegreeCelcius"  BMC
 SG_ CMC_06_Temperature_2 : 32|8@1+ (0.5,-40) [-40|86] "DegreeCelcius"  BMC

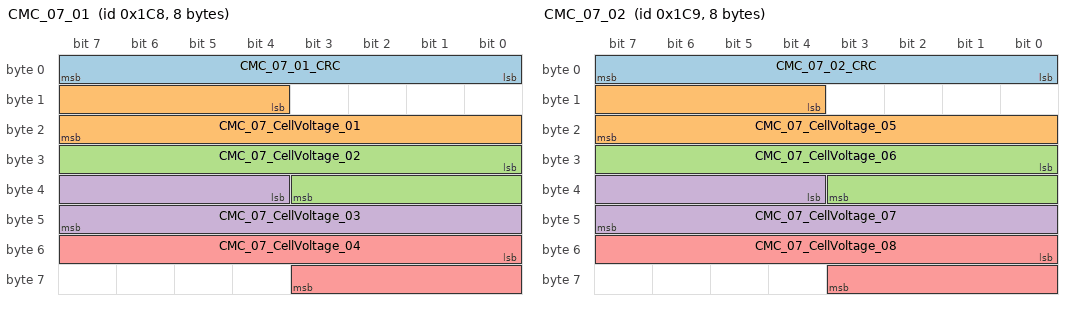
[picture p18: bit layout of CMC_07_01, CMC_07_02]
BO_ 456 CMC_07_01: 8 CMC_07
 SG_ CMC_07_01_CRC : 0|8@1+ (1,0) [0|255] ""  BMC
 SG_ CMC_07_CellVoltage_01 : 12|12@1+ (1,1000) [1000|5091] "MilliVolt"  BMC
 SG_ CMC_07_CellVoltage_02 : 24|12@1+ (1,1000) [1000|5091] "MilliVolt"  BMC
 SG_ CMC_07_CellVoltage_03 : 36|12@1+ (1,1000) [1000|5091] "MilliVolt"  BMC
 SG_ CMC_07_CellVoltage_04 : 48|12@1+ (1,1000) [1000|5091] "MilliVolt"  BMC

BO_ 457 CMC_07_02: 8 CMC_07
 SG_ CMC_07_02_CRC : 0|8@1+ (1,0) [0|255] ""  BMC
 SG_ CMC_07_CellVoltage_05 : 12|12@1+ (1,1000) [1000|5091] "MilliVolt"  BMC
 SG_ CMC_07_CellVoltage_06 : 24|12@1+ (1,1000) [1000|5091] "MilliVolt"  BMC
 SG_ CMC_07_CellVoltage_07 : 36|12@1+ (1,1000) [1000|5091] "MilliVolt"  BMC
 SG_ CMC_07_CellVoltage_08 : 48|12@1+ (1,1000) [1000|5091] "MilliVolt"  BMC

BO_ 458 CMC_07_03: 8 CMC_07
 SG_ CMC_07_03_CRC : 0|8@1+ (1,0) [0|255] ""  BMC
 SG_ CMC_07_CellVoltage_09 : 12|12@1+ (1,1000) [1000|5091] "MilliVolt"  BMC
 SG_ CMC_07_CellVoltage_10 : 24|12@1+ (1,1000) [1000|5091] "MilliVolt"  BMC
 SG_ CMC_07_CellVoltage_11 : 36|12@1+ (1,1000) [1000|5091] "MilliVolt"  BMC
 SG_ CMC_07_CellVoltage_12 : 48|12@1+ (1,1000) [1000|5091] "MilliVolt"  BMC

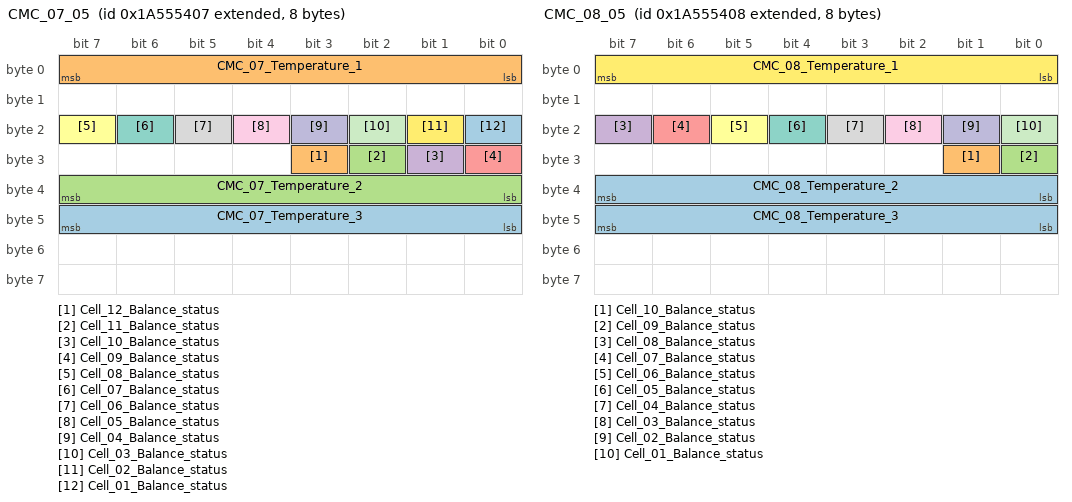
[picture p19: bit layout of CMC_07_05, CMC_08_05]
BO_ 2589283335 CMC_07_05: 8 CMC_07
 SG_ CMC_07_Temperature_3 : 40|8@1+ (0.5,-40) [-40|86] "DegreeCelcius" Vector__XXX
 SG_ Cell_12_Balance_status : 27|1@1+ (1,0) [0|1] "" Vector__XXX
 SG_ Cell_11_Balance_status : 26|1@1+ (1,0) [0|1] "" Vector__XXX
 SG_ Cell_10_Balance_status : 25|1@1+ (1,0) [0|1] "" Vector__XXX
 SG_ Cell_09_Balance_status : 24|1@1+ (1,0) [0|1] "" Vector__XXX
 SG_ Cell_08_Balance_status : 23|1@1+ (1,0) [0|1] "" Vector__XXX
 SG_ Cell_07_Balance_status : 22|1@1+ (1,0) [0|1] "" Vector__XXX
 SG_ Cell_06_Balance_status : 21|1@1+ (1,0) [0|1] "" Vector__XXX
 SG_ Cell_05_Balance_status : 20|1@1+ (1,0) [0|1] "" Vector__XXX
 SG_ Cell_04_Balance_status : 19|1@1+ (1,0) [0|1] "" Vector__XXX
 SG_ Cell_03_Balance_status : 18|1@1+ (1,0) [0|1] "" Vector__XXX
 SG_ Cell_02_Balance_status : 17|1@1+ (1,0) [0|1] "" Vector__XXX
 SG_ Cell_01_Balance_status : 16|1@1+ (1,0) [0|1] "" Vector__XXX
 SG_ CMC_07_Temperature_1 : 0|8@1+ (0.5,-40) [-40|86] "DegreeCelcius"  BMC
 SG_ CMC_07_Temperature_2 : 32|8@1+ (0.5,-40) [-40|86] "DegreeCelcius"  BMC

BO_ 460 CMC_08_01: 8 CMC_08
 SG_ CMC_08_01_CRC : 0|8@1+ (1,0) [0|255] ""  BMC
 SG_ CMC_08_CellVoltage_01 : 12|12@1+ (1,1000) [1000|5091] "MilliVolt"  BMC
 SG_ CMC_08_CellVoltage_02 : 24|12@1+ (1,1000) [1000|5091] "MilliVolt"  BMC
 SG_ CMC_08_CellVoltage_03 : 36|12@1+ (1,1000) [1000|5091] "MilliVolt"  BMC
 SG_ CMC_08_CellVoltage_04 : 48|12@1+ (1,1000) [1000|5091] "MilliVolt"  BMC

BO_ 461 CMC_08_02: 8 CMC_08
 SG_ CMC_08_02_CRC : 0|8@1+ (1,0) [0|255] ""  BMC
 SG_ CMC_08_CellVoltage_05 : 12|12@1+ (1,1000) [1000|5091] "MilliVolt"  BMC
 SG_ CMC_08_CellVoltage_06 : 24|12@1+ (1,1000) [1000|5091] "MilliVolt"  BMC
 SG_ CMC_08_CellVoltage_07 : 36|12@1+ (1,1000) [1000|5091] "MilliVolt"  BMC
 SG_ CMC_08_CellVoltage_08 : 48|12@1+ (1,1000) [1000|5091] "MilliVolt"  BMC

BO_ 462 CMC_08_03: 8 CMC_08
 SG_ CMC_08_03_CRC : 0|8@1+ (1,0) [0|255] ""  BMC
 SG_ CMC_08_CellVoltage_09 : 12|12@1+ (1,1000) [1000|5091] "MilliVolt"  BMC
 SG_ CMC_08_CellVoltage_10 : 24|12@1+ (1,1000) [1000|5091] "MilliVolt"  BMC

BO_ 2589283336 CMC_08_05: 8 CMC_08
 SG_ CMC_08_Temperature_3 : 40|8@1+ (0.5,-40) [-40|86] "DegreeCelcius" Vector__XXX
 SG_ Cell_10_Balance_status : 25|1@1+ (1,0) [0|1] "" Vector__XXX
 SG_ Cell_09_Balance_status : 24|1@1+ (1,0) [0|1] "" Vector__XXX
 SG_ Cell_08_Balance_status : 23|1@1+ (1,0) [0|1] "" Vector__XXX
 SG_ Cell_07_Balance_status : 22|1@1+ (1,0) [0|1] "" Vector__XXX
 SG_ Cell_06_Balance_status : 21|1@1+ (1,0) [0|1] "" Vector__XXX
 SG_ Cell_05_Balance_status : 20|1@1+ (1,0) [0|1] "" Vector__XXX
 SG_ Cell_04_Balance_status : 19|1@1+ (1,0) [0|1] "" Vector__XXX
 SG_ Cell_03_Balance_status : 18|1@1+ (1,0) [0|1] "" Vector__XXX
 SG_ Cell_02_Balance_status : 17|1@1+ (1,0) [0|1] "" Vector__XXX
 SG_ Cell_01_Balance_status : 16|1@1+ (1,0) [0|1] "" Vector__XXX
 SG_ CMC_08_Temperature_1 : 0|8@1+ (0.5,-40) [-40|86] "DegreeCelcius"  BMC
 SG_ CMC_08_Temperature_2 : 32|8@1+ (0.5,-40) [-40|86] "DegreeCelcius"  BMC

BA_DEF_  "BusType" STRING ;
BA_DEF_REL_ BU_BO_REL_  "Cyclic_1000ms" INT 10 1000;
BA_DEF_DEF_  "BusType" "CAN";
BA_DEF_DEF_REL_ "Cyclic_1000ms" 1000;
VAL_ 2589283340 BMC_CMC_02_BalCommand_06 255 "Not available" 254 "Error" ;
VAL_ 2589283329 Cell_12_Balance_status 1 "Active" 0 "Inactive" ;
VAL_ 2589283329 Cell_11_Balance_status 1 "Active" 0 "Inactive" ;
VAL_ 2589283329 Cell_10_Balance_status 1 "Active" 0 "Inactive" ;
VAL_ 2589283329 Cell_09_Balance_status 1 "Active" 0 "Inactive" ;
VAL_ 2589283329 Cell_08_Balance_status 1 "Active" 0 "Inactive" ;
VAL_ 2589283329 Cell_07_Balance_status 1 "Active" 0 "Inactive" ;
VAL_ 2589283329 Cell_06_Balance_status 1 "Active" 0 "Inactive" ;
VAL_ 2589283329 Cell_05_Balance_status 1 "Active" 0 "Inactive" ;
VAL_ 2589283329 Cell_04_Balance_status 1 "Active" 0 "Inactive" ;
VAL_ 2589283329 Cell_03_Balance_status 1 "Active" 0 "Inactive" ;
VAL_ 2589283329 Cell_02_Balance_status 1 "Active" 0 "Inactive" ;
VAL_ 2589283329 Cell_01_Balance_status 1 "Active" 0 "Inactive" ;
VAL_ 2589283329 CMC_01_Temperature_0 255 "Not available" 254 "Error" ;
VAL_ 2589283329 CMC_01_Temperature_4 255 "Not available" 254 "Error" ;
VAL_ 2589283329 CMC_01_Temperature_3 255 "Not available" 254 "Error" ;
VAL_ 2589283329 CMC_01_Temperature_1 255 "Not available" 254 "Error" ;
VAL_ 2589283329 CMC_01_Temperature_2 255 "Not available" 254 "Error" ;
VAL_ 2589283330 Cell_12_Balance_status 1 "Active" 0 "Inactive" ;
VAL_ 2589283330 Cell_11_Balance_status 1 "Active" 0 "Inactive" ;
VAL_ 2589283330 Cell_10_Balance_status 1 "Active" 0 "Inactive" ;
VAL_ 2589283330 Cell_09_Balance_status 1 "Active" 0 "Inactive" ;
VAL_ 2589283330 Cell_08_Balance_status 1 "Active" 0 "Inactive" ;
VAL_ 2589283330 Cell_07_Balance_status 1 "Active" 0 "Inactive" ;
VAL_ 2589283330 Cell_06_Balance_status 1 "Active" 0 "Inactive" ;
VAL_ 2589283330 Cell_05_Balance_status 1 "Active" 0 "Inactive" ;
VAL_ 2589283330 Cell_04_Balance_status 1 "Active" 0 "Inactive" ;
VAL_ 2589283330 Cell_03_Balance_status 1 "Active" 0 "Inactive" ;
VAL_ 2589283330 Cell_02_Balance_status 1 "Active" 0 "Inactive" ;
VAL_ 2589283330 Cell_01_Balance_status 1 "Active" 0 "Inactive" ;
VAL_ 2589283330 CMC_02_Temperature_4 255 "Not available" 254 "Error" ;
VAL_ 2589283330 CMC_02_Temperature_3 255 "Not available" 254 "Error" ;
VAL_ 2589283330 CMC_02_Temperature_1 255 "Not available" 254 "Error" ;
VAL_ 2589283330 CMC_02_Temperature_2 255 "Not available" 254 "Error" ;
VAL_ 2589283331 Cell_08_Balance_status 1 "Active" 0 "Inactive" ;
VAL_ 2589283331 Cell_07_Balance_status 1 "Active" 0 "Inactive" ;
VAL_ 2589283331 Cell_06_Balance_status 1 "Active" 0 "Inactive" ;
VAL_ 2589283331 Cell_05_Balance_status 1 "Active" 0 "Inactive" ;
VAL_ 2589283331 Cell_04_Balance_status 1 "Active" 0 "Inactive" ;
VAL_ 2589283331 Cell_03_Balance_status 1 "Active" 0 "Inactive" ;
VAL_ 2589283331 Cell_02_Balance_status 1 "Active" 0 "Inactive" ;
VAL_ 2589283331 Cell_01_Balance_status 1 "Active" 0 "Inactive" ;
VAL_ 2589283332 CMC_04_Temperature_3 255 "Not available" 254 "Error" ;
VAL_ 2589283332 Cell_10_Balance_status 1 "Active" 0 "Inactive" ;
VAL_ 2589283332 Cell_09_Balance_status 1 "Active" 0 "Inactive" ;
VAL_ 2589283332 Cell_08_Balance_status 1 "Active" 0 "Inactive" ;
VAL_ 2589283332 Cell_07_Balance_status 1 "Active" 0 "Inactive" ;
VAL_ 2589283332 Cell_06_Balance_status 1 "Active" 0 "Inactive" ;
VAL_ 2589283332 Cell_05_Balance_status 1 "Active" 0 "Inactive" ;
VAL_ 2589283332 Cell_04_Balance_status 1 "Active" 0 "Inactive" ;
VAL_ 2589283332 Cell_03_Balance_status 1 "Active" 0 "Inactive" ;
VAL_ 2589283332 Cell_02_Balance_status 1 "Active" 0 "Inactive" ;
VAL_ 2589283332 Cell_01_Balance_status 1 "Active" 0 "Inactive" ;
VAL_ 2589283332 CMC_04_Temperature_1 255 "Not available" 254 "Error" ;
VAL_ 2589283332 CMC_04_Temperature_2 255 "Not available" 254 "Error" ;
VAL_ 2589283333 CMC_05_Temperature_3 255 "Not available" 254 "Error" ;
VAL_ 2589283333 Cell_12_Balance_status 1 "Active" 0 "Inactive" ;
VAL_ 2589283333 Cell_11_Balance_status 1 "Active" 0 "Inactive" ;
VAL_ 2589283333 Cell_10_Balance_status 1 "Active" 0 "Inactive" ;
VAL_ 2589283333 Cell_09_Balance_status 1 "Active" 0 "Inactive" ;
VAL_ 2589283333 Cell_08_Balance_status 1 "Active" 0 "Inactive" ;
VAL_ 2589283333 Cell_07_Balance_status 1 "Active" 0 "Inactive" ;
VAL_ 2589283333 Cell_06_Balance_status 1 "Active" 0 "Inactive" ;
VAL_ 2589283333 Cell_05_Balance_status 1 "Active" 0 "Inactive" ;
VAL_ 2589283333 Cell_04_Balance_status 1 "Active" 0 "Inactive" ;
VAL_ 2589283333 Cell_03_Balance_status 1 "Active" 0 "Inactive" ;
VAL_ 2589283333 Cell_02_Balance_status 1 "Active" 0 "Inactive" ;
VAL_ 2589283333 Cell_01_Balance_status 1 "Active" 0 "Inactive" ;
VAL_ 2589283333 CMC_05_Temperature_1 255 "Not available" 254 "Error" ;
VAL_ 2589283333 CMC_05_Temperature_2 255 "Not available" 254 "Error" ;
VAL_ 2589283334 CMC_06_Temperature_3 255 "Not available" 254 "Error" ;
VAL_ 2589283334 Cell_12_Balance_status 1 "Active" 0 "Inactive" ;
VAL_ 2589283334 Cell_11_Balance_status 1 "Active" 0 "Inactive" ;
VAL_ 2589283334 Cell_10_Balance_status 1 "Active" 0 "Inactive" ;
VAL_ 2589283334 Cell_09_Balance_status 1 "Active" 0 "Inactive" ;
VAL_ 2589283334 Cell_08_Balance_status 1 "Active" 0 "Inactive" ;
VAL_ 2589283334 Cell_07_Balance_status 1 "Active" 0 "Inactive" ;
VAL_ 2589283334 Cell_06_Balance_status 1 "Active" 0 "Inactive" ;
VAL_ 2589283334 Cell_05_Balance_status 1 "Active" 0 "Inactive" ;
VAL_ 2589283334 Cell_04_Balance_status 1 "Active" 0 "Inactive" ;
VAL_ 2589283334 Cell_03_Balance_status 1 "Active" 0 "Inactive" ;
VAL_ 2589283334 Cell_02_Balance_status 1 "Active" 0 "Inactive" ;
VAL_ 2589283334 Cell_01_Balance_status 1 "Active" 0 "Inactive" ;
VAL_ 2589283334 CMC_06_Temperature_1 255 "Not available" 254 "Error" ;
VAL_ 2589283334 CMC_06_Temperature_2 255 "Not available" 254 "Error" ;
VAL_ 2589283335 CMC_07_Temperature_3 255 "Not available" 254 "Error" ;
VAL_ 2589283335 Cell_12_Balance_status 1 "Active" 0 "Inactive" ;
VAL_ 2589283335 Cell_11_Balance_status 1 "Active" 0 "Inactive" ;
VAL_ 2589283335 Cell_10_Balance_status 1 "Active" 0 "Inactive" ;
VAL_ 2589283335 Cell_09_Balance_status 1 "Active" 0 "Inactive" ;
VAL_ 2589283335 Cell_08_Balance_status 1 "Active" 0 "Inactive" ;
VAL_ 2589283335 Cell_07_Balance_status 1 "Active" 0 "Inactive" ;
VAL_ 2589283335 Cell_06_Balance_status 1 "Active" 0 "Inactive" ;
VAL_ 2589283335 Cell_05_Balance_status 1 "Active" 0 "Inactive" ;
VAL_ 2589283335 Cell_04_Balance_status 1 "Active" 0 "Inactive" ;
VAL_ 2589283335 Cell_03_Balance_status 1 "Active" 0 "Inactive" ;
VAL_ 2589283335 Cell_02_Balance_status 1 "Active" 0 "Inactive" ;
VAL_ 2589283335 Cell_01_Balance_status 1 "Active" 0 "Inactive" ;
VAL_ 2589283335 CMC_07_Temperature_1 255 "Not available" 254 "Error" ;
VAL_ 2589283335 CMC_07_Temperature_2 255 "Not available" 254 "Error" ;
VAL_ 2589283336 CMC_08_Temperature_3 255 "Not available" 254 "Error" ;
VAL_ 2589283336 Cell_10_Balance_status 1 "Active" 0 "Inactive" ;
VAL_ 2589283336 Cell_09_Balance_status 1 "Active" 0 "Inactive" ;
VAL_ 2589283336 Cell_08_Balance_status 1 "Active" 0 "Inactive" ;
VAL_ 2589283336 Cell_07_Balance_status 1 "Active" 0 "Inactive" ;
VAL_ 2589283336 Cell_06_Balance_status 1 "Active" 0 "Inactive" ;
VAL_ 2589283336 Cell_05_Balance_status 1 "Active" 0 "Inactive" ;
VAL_ 2589283336 Cell_04_Balance_status 1 "Active" 0 "Inactive" ;
VAL_ 2589283336 Cell_03_Balance_status 1 "Active" 0 "Inactive" ;
VAL_ 2589283336 Cell_02_Balance_status 1 "Active" 0 "Inactive" ;
VAL_ 2589283336 Cell_01_Balance_status 1 "Active" 0 "Inactive" ;
VAL_ 2589283336 CMC_08_Temperature_1 255 "Not available" 254 "Error" ;
VAL_ 2589283336 CMC_08_Temperature_2 255 "Not available" 254 "Error" ;
